AUTOSAR XML (schema 4-0-3)
package /AUTOSAR_Dcm/ImplementationDataTypes
  39 x impl type:
    Dcm_ProtocolType:
      category=VALUE
      base-type=uint8
      compu {0x00=DCM_OBD_ON_CAN, 0x01=DCM_OBD_ON_FLEXRAY, 0x02=DCM_OBD_ON_IP, 0x03=DCM_UDS_ON_CAN, 0x04=DCM_UDS_ON_FLEXRAY, 0x05=DCM_UDS_ON_IP, 0x06=DCM_ROE_ON_CAN, 0x07=DCM_ROE_ON_FLEXRAY, 0x08=DCM_ROE_ON_IP, 0x09=DCM_PERIODICTRANS_ON_CAN, 0x0A=DCM_PERIODICTRANS_ON_FLEXRAY, 0x0B=DCM_PERIODICTRANS_ON_IP, 0x0C=DCM_NO_ACTIVE_PROTOCOL, 0xF0=DCM_SUPPLIER_1, 0xF1=DCM_SUPPLIER_2, 0xF2=DCM_SUPPLIER_3, 0xF3=DCM_SUPPLIER_4, 0xF4=DCM_SUPPLIER_5, 0xF5=DCM_SUPPLIER_6, 0xF6=DCM_SUPPLIER_7, 0xF7=DCM_SUPPLIER_8, 0xF8=DCM_SUPPLIER_9, 0xF9=DCM_SUPPLIER_10, 0xFA=DCM_SUPPLIER_11, 0xFB=DCM_SUPPLIER_12, 0xFC=DCM_SUPPLIER_13, 0xFD=DCM_SUPPLIER_14, 0xFE=DCM_SUPPLIER_15, 0x0E=DCM_OBD_ON_UDS, 0x0F=DCM_ZEV_ON_UDS}
      range raw 0x00..0xFE
    Dcm_ResponseDataArrayType: category=ARRAY
      element RequestDataArray: array-size=512, array-size-semantics=FIXED-SIZE, implementation-data-type=uint8
    KeyArrayType_L10: category=ARRAY
      element KeyArrayType: array-size=256, array-size-semantics=FIXED-SIZE, implementation-data-type=uint8
    ScalingInfoArrayType_VINDataIdentifier: category=ARRAY
      element ScalingInfoArrayType: array-size=2, array-size-semantics=FIXED-SIZE, implementation-data-type=uint8
    Dcm_MsgLenType: category=VALUE, base-type=uint32, range raw 0..4294967295
    Dcm_PresentDateType: category=VALUE, base-type=uint8, range raw 0..255
    DataArrayType_VINDataIdentifier: category=ARRAY
      element DataArrayType: array-size=17, array-size-semantics=FIXED-SIZE, implementation-data-type=uint8
    DataArrayType_SystemSupplierECUSoftwareNumber: category=ARRAY
      element DataArrayType: array-size=4, array-size-semantics=FIXED-SIZE, implementation-data-type=uint8
    Dcm_CertExpirationDateInfoType: category=ARRAY
      element expirationDate: array-size=3, array-size-semantics=FIXED-SIZE, implementation-data-type=uint8
    Dcm_StatusType: category=VALUE, base-type=uint8, compu {0x00=DCM_E_OK, 0x08=DCM_E_REQUEST_NOT_ACCEPTED, 0x05=DCM_E_PROTOCOL_NOT_ALLOWED, 0x06=DCM_E_ROE_NOT_ACCEPTED, 0x07=DCM_E_PERIODICID_NOT_ACCEPTED, 0x11=DCM_E_COMPARE_KEY_FAILED}, range raw 0x00..0x11
    Dcm_EcuStartModeType: category=VALUE, base-type=uint8, compu {0x00=DCM_COLD_START, 0x01=DCM_WARM_START}, range raw 0x00..0x01
    KeyArrayType_L9: category=ARRAY
      element KeyArrayType: array-size=8, array-size-semantics=FIXED-SIZE, implementation-data-type=uint8
    Dcm_ReturnReadMemoryType: category=VALUE, base-type=uint8, compu {0x02=DCM_READ_FAILED, 0x03=DCM_READ_FORCE_RCRRP, 0x00=DCM_READ_OK, 0x01=DCM_READ_PENDING}, range raw 0x00..0x03
    DTRStatusType: category=VALUE, base-type=uint8, range raw 0..255
    Dcm_CertAuthorizationInfoType: category=ARRAY
      element authorization: array-size=4, array-size-semantics=FIXED-SIZE, implementation-data-type=uint8
    Dcm_ConfirmationStatusType: category=VALUE, base-type=uint8, compu {0x00=DCM_RES_POS_OK, 0x01=DCM_RES_POS_NOT_OK, 0x02=DCM_RES_NEG_OK, 0x03=DCM_RES_NEG_NOT_OK}, range raw 0x00..0x03
    DataArrayType_ActuatorControl: category=ARRAY
      element DataArrayType: array-size=1, array-size-semantics=FIXED-SIZE, implementation-data-type=uint8
    DataArrayType_SystemSupplierECUHardwareVersionNumber: category=ARRAY
      element DataArrayType: array-size=4, array-size-semantics=FIXED-SIZE, implementation-data-type=uint8
    Dcm_CertInfoType: category=STRUCTURE
      element authorization: implementation-data-type=Dcm_CertAuthorizationInfoType
      element expirationDate: implementation-data-type=Dcm_CertExpirationDateInfoType
    Dcm_NegativeResponseCodeType:
      category=VALUE
      base-type=uint8
      compu {0x00=DCM_E_POSITIVERESPONSE, 0x10=DCM_E_GENERALREJECT, 0x11=DCM_E_SERVICENOTSUPPORTED, 0x12=DCM_E_SUBFUNCTIONNOTSUPPORTED, 0x13=DCM_E_INCORRECTMESSAGELENGTHORINVALIDFORMAT, 0x14=DCM_E_RESPONSETOOLONG, 0x21=DCM_E_BUSYREPEATREQUEST, 0x22=DCM_E_CONDITIONSNOTCORRECT, 0x24=DCM_E_REQUESTSEQUENCEERROR, 0x25=DCM_E_NORESPONSEFROMSUBNETCOMPONENT, 0x26=DCM_E_FAILUREPREVENTSEXECUTIONOFREQUESTEDACTION, 0x31=DCM_E_REQUESTOUTOFRANGE, 0x33=DCM_E_SECURITYACCESSDENIED, 0x35=DCM_E_INVALIDKEY, 0x36=DCM_E_EXCEEDNUMBEROFATTEMPTS, 0x37=DCM_E_REQUIREDTIMEDELAYNOTEXPIRED, 0x70=DCM_E_UPLOADDOWNLOADNOTACCEPTED, 0x71=DCM_E_TRANSFERDATASUSPENDED, 0x72=DCM_E_GENERALPROGRAMMINGFAILURE, 0x73=DCM_E_WRONGBLOCKSEQUENCECOUNTER, 0x7E=DCM_E_SUBFUNCTIONNOTSUPPORTEDINACTIVESESSION, 0x7F=DCM_E_SERVICENOTSUPPORTEDINACTIVESESSION, 0x81=DCM_E_RPMTOOHIGH, 0x82=DCM_E_RPMTOOLOW, 0x83=DCM_E_ENGINEISRUNNING, 0x84=DCM_E_ENGINEISNOTRUNNING, 0x85=DCM_E_ENGINERUNTIMETOOLOW, 0x86=DCM_E_TEMPERATURETOOHIGH, 0x87=DCM_E_TEMPERATURETOOLOW, 0x88=DCM_E_VEHICLESPEEDTOOHIGH, 0x89=DCM_E_VEHICLESPEEDTOOLOW, 0x8A=DCM_E_THROTTLE_PEDALTOOHIGH, 0x8B=DCM_E_THROTTLE_PEDALTOOLOW, 0x8C=DCM_E_TRANSMISSIONRANGENOTINNEUTRAL, 0x8D=DCM_E_TRANSMISSIONRANGENOTINGEAR, 0x8F=DCM_E_BRAKESWITCH_NOTCLOSED, 0x90=DCM_E_SHIFTERLEVERNOTINPARK, 0x91=DCM_E_TORQUECONVERTERCLUTCHLOCKED, 0x92=DCM_E_VOLTAGETOOHIGH, 0x93=DCM_E_VOLTAGETOOLOW, 0xF0=DCM_E_CRLINTEGRITYCHECKFAILED, 0xF1=DCM_E_CRLEXPIRED, 0xF2=DCM_E_ROLEANDRIGHTOFCERTIFICATEDENIED, 0xF3=DCM_E_SECURITYACCESSDENIEDFRONCGW, 0xF4=DCM_E_LOWERVERSIONDOWNLOADATTEMPT, 0xF5=DCM_E_SERVICENOTSUPPORTEDINACTIVECONNECTION, 0xF6=DCM_E_VMSCNC_6, 0xF7=DCM_E_VMSCNC_7, 0xF8=DCM_E_VMSCNC_8, 0xF9=DCM_E_VMSCNC_9, 0xFA=DCM_E_VMSCNC_A, 0xFB=DCM_E_VMSCNC_B, 0xFC=DCM_E_VMSCNC_C, 0xFD=DCM_E_VMSCNC_D, 0xFE=DCM_E_VMSCNC_E, 0x50=DCM_E_CERTIFICATEVERIFICATIONFAILEDINVALIDTIMEPERIOD, 0x51=DCM_E_CERTIFICATEVERIFICATIONFAILEDINVALIDSIGNATURE, 0x52=DCM_E_CERTIFICATEVERIFICATIONFAILEDINVALIDCHAINOFTRUST, 0x53=DCM_E_CERTIFICATEVERIFICATIONFAILEDINVALIDTYPE, 0x54=DCM_E_CERTIFICATEVERIFICATIONFAILEDINVALIDFORMAT, 0x55=DCM_E_CERTIFICATEVERIFICATIONFAILEDINVALIDCONTENT, 0x56=DCM_E_CERTIFICATEVERIFICATIONFAILEDINVALIDSCOPE, 0x57=DCM_E_CERTIFICATEVERIFICATIONFAILEDINVALIDCERTIFICATE, 0x58=DCM_E_OWNERSHIPVERIFICATIONFAILED, 0x59=DCM_E_CHALLENGECALCULATIONFAILED, 0x5A=DCM_E_SETTINGACCESSRIGHTSFAILED, 0x5B=DCM_E_SESSIONKEYCREATIONDERIVATIONFAILED, 0x5C=DCM_E_CONFIGURATIONDATAUSAGEFAILED, 0x5D=DCM_E_DEAUTHENTICATIONFAILED, 0x34=DCM_E_AUTHENTICATIONREQUIRED}
      range raw 0x00..0xFF
    DataArrayType_RPM: category=ARRAY
      element DataArrayType: array-size=2, array-size-semantics=FIXED-SIZE, implementation-data-type=uint8
    Dcm_SesCtrlType: category=VALUE, base-type=uint8, compu {0x01=DCM_DEFAULT_SESSION, 0x02=DCM_PROGRAMMING_SESSION, 0x03=DCM_EXTENDED_DIAGNOSTIC_SESSION, 0x04=DCM_SAFETY_SYSTEM_DIAGNOSTIC_SESSION, 0x10=DCM_EXTENDED_DIAGNOSTIC_MODE_10H, 0x05=DCM_ECU_PROGRAMMING_MODE_05H, 0x50=DCM_QUIESCENT_CURRENT_DIAGNOSTIC_MODE_START, 0x51=DCM_SLEEP_MODE_START_REQUEST, 0xFF=DCM_ALL_SESSION_LEVEL}, range raw 0x01..0xFF
    SeedArrayType_L10: category=ARRAY
      element SeedArrayType: array-size=8, array-size-semantics=FIXED-SIZE, implementation-data-type=uint8
    Dcm_IdContextType: category=VALUE, base-type=uint8, range raw 0..255
    Dcm_CommunicationModeType:
      category=VALUE
      base-type=uint8
      compu {0x00=DCM_ENABLE_RX_TX_NORM, 0x01=DCM_ENABLE_RX_DISABLE_TX_NORM, 0x02=DCM_DISABLE_RX_ENABLE_TX_NORM, 0x03=DCM_DISABLE_RX_TX_NORMAL, 0x04=DCM_ENABLE_RX_TX_NM, 0x05=DCM_ENABLE_RX_DISABLE_TX_NM, 0x06=DCM_DISABLE_RX_ENABLE_TX_NM, 0x07=DCM_DISABLE_RX_TX_NM, 0x08=DCM_ENABLE_RX_TX_NORM_NM, 0x09=DCM_ENABLE_RX_DISABLE_TX_NORM_NM, 0x0A=DCM_DISABLE_RX_ENABLE_TX_NORM_NM, 0x0B=DCM_DISABLE_RX_TX_NORM_NM, 0x03=DCM_DISABLE_RX_TX_NORM}
      range raw 0x00..0x0B
    DataArrayType_VehicleManufacturerECUSoftwareVersionNumber: category=ARRAY
      element DataArrayType: array-size=17, array-size-semantics=FIXED-SIZE, implementation-data-type=uint8
    RequestDataArray: category=ARRAY
      element RequestDataArray: array-size=2050, array-size-semantics=FIXED-SIZE, implementation-data-type=uint8
    Dcm_ProgConditionsType: category=STRUCTURE
      9 x element, all with category=TYPE_REFERENCE:
        ConnectionId: implementation-data-type=uint16
        TesterSourceAddr: implementation-data-type=uint16
        ProtocolId: implementation-data-type=uint8
        Sid: implementation-data-type=uint8
        SubFncId: implementation-data-type=uint8
        ReprogramingRequest: implementation-data-type=boolean
        ApplUpdated: implementation-data-type=boolean
        ResponseRequired: implementation-data-type=boolean
        SecLvInfo: implementation-data-type=uint8
    Dcm_RoeStateType: category=VALUE, base-type=uint8, compu {0x00=DCM_ROE_ACTIVE, 0x01=DCM_ROE_UNACTIVE}, range raw 0x00..0x01
    DataArrayType_ECT: category=ARRAY
      element DataArrayType: array-size=1, array-size-semantics=FIXED-SIZE, implementation-data-type=uint8
    Dcm_ReturnWriteMemoryType: category=VALUE, base-type=uint8, compu {0x02=DCM_WRITE_FAILED, 0x03=DCM_WRITE_FORCE_RCRRP, 0x00=DCM_WRITE_OK, 0x01=DCM_WRITE_PENDING}, range raw 0x00..0x03
    DataArrayType_BatVolt: category=ARRAY
      element DataArrayType: array-size=1, array-size-semantics=FIXED-SIZE, implementation-data-type=uint8
    SeedArrayType_L9: category=ARRAY
      element SeedArrayType: array-size=8, array-size-semantics=FIXED-SIZE, implementation-data-type=uint8
    DataArrayType_VehicleSpeed: category=ARRAY
      element DataArrayType: array-size=1, array-size-semantics=FIXED-SIZE, implementation-data-type=uint8
    ScalingInfoArrayType_VehicleSpeed: category=ARRAY
      element ScalingInfoArrayType: array-size=9, array-size-semantics=FIXED-SIZE, implementation-data-type=uint8
    Dcm_SecLevelType: category=VALUE, base-type=uint8, compu {0x00=DCM_SEC_LEV_LOCKED, 0x01=DCM_SEC_LEV_L1, 0x09=DCM_SEC_LEV_L9, 0x21=DCM_SEC_LEV_L21, 0xFF=DCM_SEC_LEV_ALL}, range raw 0x00..0xFF
    Dcm_OpStatusType: category=VALUE, base-type=uint8, compu {0x00=DCM_INITIAL, 0x01=DCM_PENDING, 0x02=DCM_CANCEL, 0x03=DCM_FORCE_RCRRP_OK}, range raw 0x00..0x03
    Dcm_MsgItemType: category=VALUE, base-type=uint8, range raw 0..255
    Dcm_CerHolderReferenceInfoType: category=ARRAY
      element Dcm_CerHolderReferenceInfoType: array-size=16, array-size-semantics=FIXED-SIZE, implementation-data-type=uint8
package /AUTOSAR_Dcm/ClientServerInterfaces
  16 x client server interface, all with is-service=true:
    DataServices_VINDataIdentifier
      4 x operation, all with possible-error=DataServices_VINDataIdentifier/E_NOT_OK:
        ReadData
          arg Data: type=DataArrayType_VINDataIdentifier, direction=OUT
        GetScalingInformation
          arg ScalingInfo: type=ScalingInfoArrayType_VINDataIdentifier, direction=OUT
          arg ErrorCode: type=Dcm_NegativeResponseCodeType, direction=OUT
        WriteData
          arg Data: type=DataArrayType_VINDataIdentifier, direction=IN
          arg ErrorCode: type=Dcm_NegativeResponseCodeType, direction=OUT
        ConditionCheckRead
          arg ErrorCode: type=Dcm_NegativeResponseCodeType, direction=OUT
      error E_NOT_OK: error-code=1
      error DCM_E_PENDING: error-code=10
    DataServices_VehicleManufacturerECUSoftwareVersionNumber
      operation ReadData: possible-error=DataServices_VehicleManufacturerECUSoftwareVersionNumber/E_NOT_OK
        arg Data: type=DataArrayType_VehicleManufacturerECUSoftwareVersionNumber, direction=OUT
      operation ConditionCheckRead: possible-error=DataServices_VehicleManufacturerECUSoftwareVersionNumber/E_NOT_OK
        arg ErrorCode: type=Dcm_NegativeResponseCodeType, direction=OUT
      error E_NOT_OK: error-code=1
      error DCM_E_PENDING: error-code=10
    SecurityAccess_L9
      4 x operation:
        GetSecurityAttemptCounter: possible-error=[SecurityAccess_L9/E_NOT_OK, SecurityAccess_L9/DCM_E_PENDING]
          arg OpStatus: type=Dcm_OpStatusType, direction=IN
          arg AttemptCounter: type=uint8, direction=OUT
        GetSeed: possible-error=[SecurityAccess_L9/E_NOT_OK, SecurityAccess_L9/DCM_E_PENDING]
          arg OpStatus: type=Dcm_OpStatusType, direction=IN
          arg Seed: type=SeedArrayType_L9, direction=OUT
          arg ErrorCode: type=Dcm_NegativeResponseCodeType, direction=OUT
        CompareKey: possible-error=[SecurityAccess_L9/E_NOT_OK, SecurityAccess_L9/DCM_E_PENDING, SecurityAccess_L9/DCM_E_COMPARE_KEY_FAILED]
          arg Key: type=KeyArrayType_L9, direction=IN
          arg OpStatus: type=Dcm_OpStatusType, direction=IN
        SetSecurityAttemptCounter: possible-error=[SecurityAccess_L9/E_NOT_OK, SecurityAccess_L9/DCM_E_PENDING]
          arg OpStatus: type=Dcm_OpStatusType, direction=IN
          arg AttemptCounter: type=uint8, direction=IN
      error E_NOT_OK: error-code=1
      error DCM_E_PENDING: error-code=10
      error DCM_E_COMPARE_KEY_FAILED: error-code=11
    CallbackDCMPresentDate
      operation GetPresentDate: possible-error=CallbackDCMPresentDate/E_NOT_OK
        arg Date: type=Dcm_PresentDateType, direction=OUT
      error E_NOT_OK: error-code=1
    DataServices_ECT
      operation ReadData: possible-error=DataServices_ECT/E_NOT_OK
        arg Data: type=DataArrayType_ECT, direction=OUT
      operation WriteData: possible-error=DataServices_ECT/E_NOT_OK
        arg Data: type=DataArrayType_ECT, direction=IN
        arg ErrorCode: type=Dcm_NegativeResponseCodeType, direction=OUT
      operation ConditionCheckRead: possible-error=DataServices_ECT/E_NOT_OK
        arg ErrorCode: type=Dcm_NegativeResponseCodeType, direction=OUT
      error E_NOT_OK: error-code=1
      error DCM_E_PENDING: error-code=10
    DataServices_VehicleSpeed
      operation ReadData: possible-error=DataServices_VehicleSpeed/E_NOT_OK
        arg Data: type=DataArrayType_VehicleSpeed, direction=OUT
      operation GetScalingInformation: possible-error=DataServices_VehicleSpeed/E_NOT_OK
        arg ScalingInfo: type=ScalingInfoArrayType_VehicleSpeed, direction=OUT
        arg ErrorCode: type=Dcm_NegativeResponseCodeType, direction=OUT
      operation ConditionCheckRead: possible-error=DataServices_VehicleSpeed/E_NOT_OK
        arg ErrorCode: type=Dcm_NegativeResponseCodeType, direction=OUT
      error E_NOT_OK: error-code=1
      error DCM_E_PENDING: error-code=10
    SecurityAccess_L10
      4 x operation:
        GetSecurityAttemptCounter: possible-error=[SecurityAccess_L10/E_NOT_OK, SecurityAccess_L10/DCM_E_PENDING]
          arg OpStatus: type=Dcm_OpStatusType, direction=IN
          arg AttemptCounter: type=uint8, direction=OUT
        GetSeed: possible-error=[SecurityAccess_L10/E_NOT_OK, SecurityAccess_L10/DCM_E_PENDING]
          arg OpStatus: type=Dcm_OpStatusType, direction=IN
          arg Seed: type=SeedArrayType_L10, direction=OUT
          arg ErrorCode: type=Dcm_NegativeResponseCodeType, direction=OUT
        CompareKey: possible-error=[SecurityAccess_L10/E_NOT_OK, SecurityAccess_L10/DCM_E_PENDING, SecurityAccess_L10/DCM_E_COMPARE_KEY_FAILED]
          arg Key: type=KeyArrayType_L10, direction=IN
          arg OpStatus: type=Dcm_OpStatusType, direction=IN
        SetSecurityAttemptCounter: possible-error=[SecurityAccess_L10/E_NOT_OK, SecurityAccess_L10/DCM_E_PENDING]
          arg OpStatus: type=Dcm_OpStatusType, direction=IN
          arg AttemptCounter: type=uint8, direction=IN
      error E_NOT_OK: error-code=1
      error DCM_E_PENDING: error-code=10
      error DCM_E_COMPARE_KEY_FAILED: error-code=11
    CallbackDCMRequestServices
      operation StopProtocol: possible-error=CallbackDCMRequestServices/E_NOT_OK
        arg ProtocolID: type=Dcm_ProtocolType, direction=IN
      operation StartProtocol: possible-error=[CallbackDCMRequestServices/E_NOT_OK, E_PROTOCOL_NOT_ALLOWED]
        arg ProtocolID: type=Dcm_ProtocolType, direction=IN
      error E_NOT_OK: error-code=1
      error E_PROTOCOL_NOT_ALLOWED: error-code=5
    DataServices_SystemSupplierECUHardwareVersionNumber
      operation ReadData: possible-error=DataServices_SystemSupplierECUHardwareVersionNumber/E_NOT_OK
        arg Data: type=DataArrayType_SystemSupplierECUHardwareVersionNumber, direction=OUT
      operation ConditionCheckRead: possible-error=DataServices_SystemSupplierECUHardwareVersionNumber/E_NOT_OK
        arg ErrorCode: type=Dcm_NegativeResponseCodeType, direction=OUT
      error E_NOT_OK: error-code=1
      error DCM_E_PENDING: error-code=10
    DataServices_SystemSupplierECUSoftwareNumber
      operation ReadData: possible-error=DataServices_SystemSupplierECUSoftwareNumber/E_NOT_OK
        arg Data: type=DataArrayType_SystemSupplierECUSoftwareNumber, direction=OUT
      operation ConditionCheckRead: possible-error=DataServices_SystemSupplierECUSoftwareNumber/E_NOT_OK
        arg ErrorCode: type=Dcm_NegativeResponseCodeType, direction=OUT
      error E_NOT_OK: error-code=1
      error DCM_E_PENDING: error-code=10
    DCMServices
      6 x operation, all with possible-error=DCMServices/E_NOT_OK:
        ResetToDefaultSession
        GetCertificationInfo
          arg CertInfo: type=Dcm_CertInfoType, direction=OUT
        GetSecurityLevel
          arg SecLevel: type=Dcm_SecLevelType, direction=OUT
        GetActiveProtocol
          arg ActiveProtocol: type=Dcm_ProtocolType, direction=OUT
        GetCertHolderReference
          arg CertHolderReferenceInfo: type=Dcm_CerHolderReferenceInfoType, direction=OUT
        GetSesCtrlType
          arg SesCtrlType: type=Dcm_SesCtrlType, direction=OUT
      error E_NOT_OK: error-code=1
    DataServices_ActuatorControl
      7 x operation, all with possible-error=DataServices_ActuatorControl/E_NOT_OK:
        ShortTermAdjustment
          arg ControlStateInfo: type=DataArrayType_ActuatorControl, direction=IN
          arg ErrorCode: type=Dcm_NegativeResponseCodeType, direction=OUT
        ReturnControlToECU
          arg ErrorCode: type=Dcm_NegativeResponseCodeType, direction=OUT
        ReadData
          arg Data: type=DataArrayType_ActuatorControl, direction=OUT
        WriteData
          arg Data: type=DataArrayType_ActuatorControl, direction=IN
          arg ErrorCode: type=Dcm_NegativeResponseCodeType, direction=OUT
        FreezeCurrentState
          arg ErrorCode: type=Dcm_NegativeResponseCodeType, direction=OUT
        ConditionCheckRead
          arg ErrorCode: type=Dcm_NegativeResponseCodeType, direction=OUT
        ResetToDefault
          arg ErrorCode: type=Dcm_NegativeResponseCodeType, direction=OUT
      error E_NOT_OK: error-code=1
      error DCM_E_PENDING: error-code=10
    DTRServices
      operation GetDTRValue: possible-error=DTRServices/E_NOT_OK
        5 x arg:
          Opstatus: type=Dcm_OpStatusType, direction=IN
          Testval: type=uint16, direction=OUT
          Minlimit: type=uint16, direction=OUT
          Maxlimit: type=uint16, direction=OUT
          Status: type=DTRStatusType, direction=OUT
      error E_NOT_OK: error-code=1
    ServiceRequestNotification
      operation Confirmation: possible-error=ServiceRequestNotification/E_NOT_OK
        4 x arg, all with direction=IN:
          SID: type=uint8
          ReqType: type=uint8
          SourceAddress: type=uint16
          ConfirmationStatus: type=Dcm_ConfirmationStatusType
      operation Indication: possible-error=[ServiceRequestNotification/E_NOT_OK, E_REQUEST_NOT_ACCEPTED]
        6 x arg:
          SID: type=uint8, direction=IN
          RequestData: type=RequestDataArray, direction=IN
          DataSize: type=uint16, direction=IN
          ReqType: type=uint8, direction=IN
          SourceAddress: type=uint16, direction=IN
          ErrorCode: type=Dcm_NegativeResponseCodeType, direction=OUT
      error E_NOT_OK: error-code=1
      error E_REQUEST_NOT_ACCEPTED: error-code=8
    DataServices_RPM
      6 x operation, all with possible-error=DataServices_RPM/E_NOT_OK:
        ShortTermAdjustment
          arg ControlStateInfo: type=DataArrayType_RPM, direction=IN
          arg ErrorCode: type=Dcm_NegativeResponseCodeType, direction=OUT
        ReturnControlToECU
          arg ErrorCode: type=Dcm_NegativeResponseCodeType, direction=OUT
        ReadData
          arg Data: type=DataArrayType_RPM, direction=OUT
        WriteData
          arg Data: type=DataArrayType_RPM, direction=IN
          arg ErrorCode: type=Dcm_NegativeResponseCodeType, direction=OUT
        FreezeCurrentState
          arg ErrorCode: type=Dcm_NegativeResponseCodeType, direction=OUT
        ConditionCheckRead
          arg ErrorCode: type=Dcm_NegativeResponseCodeType, direction=OUT
      error E_NOT_OK: error-code=1
      error DCM_E_PENDING: error-code=10
    DataServices_BatVolt
      operation ReadData: possible-error=DataServices_BatVolt/E_NOT_OK
        arg Data: type=DataArrayType_BatVolt, direction=OUT
      operation WriteData: possible-error=DataServices_BatVolt/E_NOT_OK
        arg Data: type=DataArrayType_BatVolt, direction=IN
        arg ErrorCode: type=Dcm_NegativeResponseCodeType, direction=OUT
      operation ConditionCheckRead: possible-error=DataServices_BatVolt/E_NOT_OK
        arg ErrorCode: type=Dcm_NegativeResponseCodeType, direction=OUT
      error E_NOT_OK: error-code=1
      error DCM_E_PENDING: error-code=10
package /AUTOSAR_Dcm/ServiceSwComponentTypes
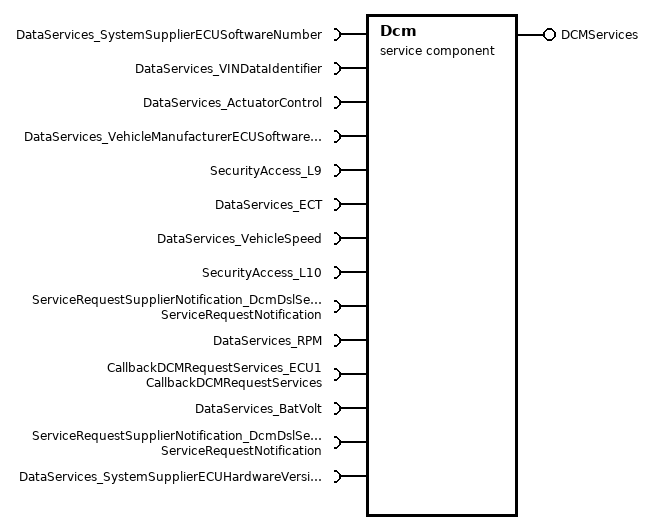
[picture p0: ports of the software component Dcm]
  service sw component type Dcm
    provide port DCMServices: provided-interface=DCMServices
      provided-com-specs:
        operation=ResetToDefaultSession, queue-length=1
        operation=GetCertificationInfo, queue-length=1
        operation=GetSecurityLevel, queue-length=1
        operation=GetActiveProtocol, queue-length=1
        operation=GetCertHolderReference, queue-length=1
        operation=GetSesCtrlType, queue-length=1
    14 x require port:
      DataServices_SystemSupplierECUSoftwareNumber: required-interface=DataServices_SystemSupplierECUSoftwareNumber
        required-com-specs:
          DataServices_SystemSupplierECUSoftwareNumber/ReadData
          DataServices_SystemSupplierECUSoftwareNumber/ConditionCheckRead
      DataServices_VINDataIdentifier: required-interface=DataServices_VINDataIdentifier
        required-com-specs:
          DataServices_VINDataIdentifier/ReadData
          DataServices_VINDataIdentifier/GetScalingInformation
          DataServices_VINDataIdentifier/WriteData
          DataServices_VINDataIdentifier/ConditionCheckRead
      DataServices_ActuatorControl: required-interface=DataServices_ActuatorControl
        required-com-specs:
          DataServices_ActuatorControl/ShortTermAdjustment
          DataServices_ActuatorControl/ReturnControlToECU
          DataServices_ActuatorControl/ReadData
          DataServices_ActuatorControl/WriteData
          DataServices_ActuatorControl/FreezeCurrentState
          DataServices_ActuatorControl/ConditionCheckRead
          ResetToDefault
      DataServices_VehicleManufacturerECUSoftwareVersionNumber: required-interface=DataServices_VehicleManufacturerECUSoftwareVersionNumber
        required-com-specs:
          DataServices_VehicleManufacturerECUSoftwareVersionNumber/ReadData
          DataServices_VehicleManufacturerECUSoftwareVersionNumber/ConditionCheckRead
      SecurityAccess_L9: required-interface=SecurityAccess_L9
        required-com-specs:
          SecurityAccess_L9/GetSecurityAttemptCounter
          SecurityAccess_L9/GetSeed
          SecurityAccess_L9/CompareKey
          SecurityAccess_L9/SetSecurityAttemptCounter
      DataServices_ECT: required-com-specs=[DataServices_ECT/ReadData, DataServices_ECT/WriteData, DataServices_ECT/ConditionCheckRead], required-interface=DataServices_ECT
      DataServices_VehicleSpeed: required-interface=DataServices_VehicleSpeed
        required-com-specs:
          DataServices_VehicleSpeed/ReadData
          DataServices_VehicleSpeed/GetScalingInformation
          DataServices_VehicleSpeed/ConditionCheckRead
      SecurityAccess_L10: required-interface=SecurityAccess_L10
        required-com-specs:
          SecurityAccess_L10/GetSecurityAttemptCounter
          SecurityAccess_L10/GetSeed
          SecurityAccess_L10/CompareKey
          SecurityAccess_L10/SetSecurityAttemptCounter
      ServiceRequestSupplierNotification_DcmDslServiceRequestSupplierNotification0: required-com-specs=[Confirmation, Indication], required-interface=ServiceRequestNotification
      DataServices_RPM: required-interface=DataServices_RPM
        required-com-specs:
          DataServices_RPM/ShortTermAdjustment
          DataServices_RPM/ReturnControlToECU
          DataServices_RPM/ReadData
          DataServices_RPM/WriteData
          DataServices_RPM/FreezeCurrentState
          DataServices_RPM/ConditionCheckRead
      CallbackDCMRequestServices_ECU1: required-com-specs=[StopProtocol, StartProtocol], required-interface=CallbackDCMRequestServices
      DataServices_BatVolt: required-com-specs=[DataServices_BatVolt/ReadData, DataServices_BatVolt/WriteData, DataServices_BatVolt/ConditionCheckRead], required-interface=DataServices_BatVolt
      ServiceRequestSupplierNotification_DcmDslServiceRequestSupplierNotification1: required-com-specs=[Confirmation, Indication], required-interface=ServiceRequestNotification
      DataServices_SystemSupplierECUHardwareVersionNumber: required-interface=DataServices_SystemSupplierECUHardwareVersionNumber
        required-com-specs:
          DataServices_SystemSupplierECUHardwareVersionNumber/ReadData
          DataServices_SystemSupplierECUHardwareVersionNumber/ConditionCheckRead
    behavior DcmInternalBehavior: handle-termination-and-restart=NO-SUPPORT, included-data-type-set=data-type=[Dcm_ProtocolType, Dcm_ResponseDataArrayType, KeyArrayType_L10, ScalingInfoArrayType_VINDataIdentifier, Dcm_MsgLenType, Dcm_PresentDateType, DataArrayType_VINDataIdentifier, DataArrayType_SystemSupplierECUSoftwareNumber, Dcm_CertExpirationDateInfoType, Dcm_StatusType, Dcm_EcuStartModeType, KeyArrayType_L9, Dcm_ReturnReadMemoryType, DTRStatusType, Dcm_CertAuthorizationInfoType, Dcm_ConfirmationStatusType, DataArrayType_ActuatorControl, DataArrayType_SystemSupplierECUHardwareVersionNumber, Dcm_CertInfoType, Dcm_NegativeResponseCodeType, DataArrayType_RPM, Dcm_SesCtrlType, SeedArrayType_L10, Dcm_IdContextType, Dcm_CommunicationModeType, DataArrayType_VehicleManufacturerECUSoftwareVersionNumber, RequestDataArray, Dcm_ProgConditionsType, Dcm_RoeStateType, DataArrayType_ECT, Dcm_ReturnWriteMemoryType, DataArrayType_BatVolt, SeedArrayType_L9, DataArrayType_VehicleSpeed, ScalingInfoArrayType_VehicleSpeed, Dcm_SecLevelType, Dcm_OpStatusType, Dcm_MsgItemType, Dcm_CerHolderReferenceInfoType]
      6 x operation invoked event:
        OIE_DCMServices_ResetToDefaultSession: start-on-event=ResetToDefaultSession, operation=DCMServices.ResetToDefaultSession
        OIE_DCMServices_GetCertificationInfo: start-on-event=GetCertificationInfo, operation=DCMServices.GetCertificationInfo
        OIE_DCMServices_GetSecurityLevel: start-on-event=GetSecurityLevel, operation=DCMServices.GetSecurityLevel
        OIE_DCMServices_GetActiveProtocol: start-on-event=GetActiveProtocol, operation=DCMServices.GetActiveProtocol
        OIE_DCMServices_GetCertHolderReference: start-on-event=GetCertHolderReference, operation=DCMServices.GetCertHolderReference
        OIE_DCMServices_GetSesCtrlType: start-on-event=GetSesCtrlType, operation=DCMServices.GetSesCtrlType
      7 x runnable:
        ResetToDefaultSession: can-be-invoked-concurrently=true, symbol=Dcm_ResetToDefaultSession
        GetCertificationInfo: can-be-invoked-concurrently=true, symbol=Dcm_GetCertificationInfo
        GetSecurityLevel: can-be-invoked-concurrently=true, symbol=Dcm_GetSecurityLevel
        GetActiveProtocol: can-be-invoked-concurrently=true, symbol=Dcm_GetActiveProtocol
        GetCertHolderReference: can-be-invoked-concurrently=true, symbol=Dcm_GetCertHolderReference
        GetSesCtrlType: can-be-invoked-concurrently=true, symbol=Dcm_GetSesCtrlType
        MainFunction: symbol=Dcm_MainFunction
          46 x sync call, all with timeout=0:
            SSCP_DataServices_SystemSupplierECUSoftwareNumber_ReadData: operation=DataServices_SystemSupplierECUSoftwareNumber.ReadData
            SSCP_DataServices_SystemSupplierECUSoftwareNumber_ConditionCheckRead: operation=DataServices_SystemSupplierECUSoftwareNumber.ConditionCheckRead
            SSCP_DataServices_VINDataIdentifier_ReadData: operation=DataServices_VINDataIdentifier.ReadData
            SSCP_DataServices_VINDataIdentifier_GetScalingInformation: operation=DataServices_VINDataIdentifier.GetScalingInformation
            SSCP_DataServices_VINDataIdentifier_WriteData: operation=DataServices_VINDataIdentifier.WriteData
            SSCP_DataServices_VINDataIdentifier_ConditionCheckRead: operation=DataServices_VINDataIdentifier.ConditionCheckRead
            SSCP_DataServices_ActuatorControl_ShortTermAdjustment: operation=DataServices_ActuatorControl.ShortTermAdjustment
            SSCP_DataServices_ActuatorControl_ReturnControlToECU: operation=DataServices_ActuatorControl.ReturnControlToECU
            SSCP_DataServices_ActuatorControl_ReadData: operation=DataServices_ActuatorControl.ReadData
            SSCP_DataServices_ActuatorControl_WriteData: operation=DataServices_ActuatorControl.WriteData
            SSCP_DataServices_ActuatorControl_FreezeCurrentState: operation=DataServices_ActuatorControl.FreezeCurrentState
            SSCP_DataServices_ActuatorControl_ConditionCheckRead: operation=DataServices_ActuatorControl.ConditionCheckRead
            SSCP_DataServices_ActuatorControl_ResetToDefault: operation=DataServices_ActuatorControl.ResetToDefault
            SSCP_DataServices_VehicleManufacturerECUSoftwareVersionNumber_ReadData: operation=DataServices_VehicleManufacturerECUSoftwareVersionNumber.ReadData
            SSCP_DataServices_VehicleManufacturerECUSoftwareVersionNumber_ConditionCheckRead: operation=DataServices_VehicleManufacturerECUSoftwareVersionNumber.ConditionCheckRead
            SSCP_SecurityAccess_L9_GetSecurityAttemptCounter: operation=SecurityAccess_L9.GetSecurityAttemptCounter
            SSCP_SecurityAccess_L9_GetSeed: operation=SecurityAccess_L9.GetSeed
            SSCP_SecurityAccess_L9_CompareKey: operation=SecurityAccess_L9.CompareKey
            SSCP_SecurityAccess_L9_SetSecurityAttemptCounter: operation=SecurityAccess_L9.SetSecurityAttemptCounter
            SSCP_DataServices_ECT_ReadData: operation=DataServices_ECT.ReadData
            SSCP_DataServices_ECT_WriteData: operation=DataServices_ECT.WriteData
            SSCP_DataServices_ECT_ConditionCheckRead: operation=DataServices_ECT.ConditionCheckRead
            SSCP_DataServices_VehicleSpeed_ReadData: operation=DataServices_VehicleSpeed.ReadData
            SSCP_DataServices_VehicleSpeed_GetScalingInformation: operation=DataServices_VehicleSpeed.GetScalingInformation
            SSCP_DataServices_VehicleSpeed_ConditionCheckRead: operation=DataServices_VehicleSpeed.ConditionCheckRead
            SSCP_SecurityAccess_L10_GetSecurityAttemptCounter: operation=SecurityAccess_L10.GetSecurityAttemptCounter
            SSCP_SecurityAccess_L10_GetSeed: operation=SecurityAccess_L10.GetSeed
            SSCP_SecurityAccess_L10_CompareKey: operation=SecurityAccess_L10.CompareKey
            SSCP_SecurityAccess_L10_SetSecurityAttemptCounter: operation=SecurityAccess_L10.SetSecurityAttemptCounter
            SSCP_ServiceRequestSupplierNotification_DcmDslServiceRequestSupplierNotification0_Confirmation: operation=ServiceRequestSupplierNotification_DcmDslServiceRequestSupplierNotification0.Confirmation
            SSCP_ServiceRequestSupplierNotification_DcmDslServiceRequestSupplierNotification0_Indication: operation=ServiceRequestSupplierNotification_DcmDslServiceRequestSupplierNotification0.Indication
            SSCP_DataServices_RPM_ShortTermAdjustment: operation=DataServices_RPM.ShortTermAdjustment
            SSCP_DataServices_RPM_ReturnControlToECU: operation=DataServices_RPM.ReturnControlToECU
            SSCP_DataServices_RPM_ReadData: operation=DataServices_RPM.ReadData
            SSCP_DataServices_RPM_WriteData: operation=DataServices_RPM.WriteData
            SSCP_DataServices_RPM_FreezeCurrentState: operation=DataServices_RPM.FreezeCurrentState
            SSCP_DataServices_RPM_ConditionCheckRead: operation=DataServices_RPM.ConditionCheckRead
            SSCP_CallbackDCMRequestServices_ECU1_StopProtocol: operation=CallbackDCMRequestServices_ECU1.StopProtocol
            SSCP_CallbackDCMRequestServices_ECU1_StartProtocol: operation=CallbackDCMRequestServices_ECU1.StartProtocol
            SSCP_DataServices_BatVolt_ReadData: operation=DataServices_BatVolt.ReadData
            SSCP_DataServices_BatVolt_WriteData: operation=DataServices_BatVolt.WriteData
            SSCP_DataServices_BatVolt_ConditionCheckRead: operation=DataServices_BatVolt.ConditionCheckRead
            SSCP_ServiceRequestSupplierNotification_DcmDslServiceRequestSupplierNotification1_Confirmation: operation=ServiceRequestSupplierNotification_DcmDslServiceRequestSupplierNotification1.Confirmation
            SSCP_ServiceRequestSupplierNotification_DcmDslServiceRequestSupplierNotification1_Indication: operation=ServiceRequestSupplierNotification_DcmDslServiceRequestSupplierNotification1.Indication
            SSCP_DataServices_SystemSupplierECUHardwareVersionNumber_ReadData: operation=DataServices_SystemSupplierECUHardwareVersionNumber.ReadData
            SSCP_DataServices_SystemSupplierECUHardwareVersionNumber_ConditionCheckRead: operation=DataServices_SystemSupplierECUHardwareVersionNumber.ConditionCheckRead
  swc implementation Dcm_SwcImplementation: programming-language=C, sw-version=1.0.0.0, swc-bsw-mapping=SwcBswMapping_Dcm, vendor-id=0, behavior=DcmInternalBehavior
    code-descriptors:
      code CodeDescriptor: artifact-descriptors=autosar-engineering-object={short-label=Dcm_LibObjects, category=SWLIB, domain=AUTOSAR_DCM}
    resource consumption ResourceConsumption
  swc bsw mapping SwcBswMapping_Dcm: bsw-behavior=InternalBehavior_Dcm, swc-bsw-runnable-mapping{bsw-entity=BswSE_Dcm_MainFunction, swc-runnable=MainFunction}, swc-behavior=DcmInternalBehavior
